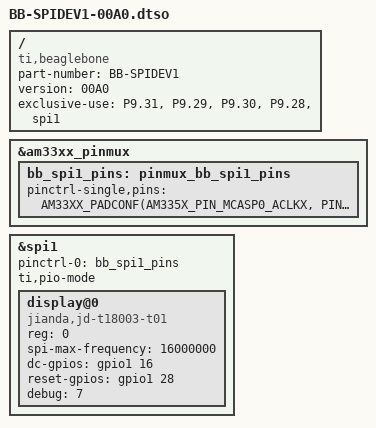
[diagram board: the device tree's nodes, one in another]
/*
 * Copyright (C) 2013 CircuitCo
 *
 * Virtual cape for SPI1 on connector pins P9.29 P9.31 P9.30 P9.28
 *
 * This program is free software; you can redistribute it and/or modify
 * it under the terms of the GNU General Public License version 2 as
 * published by the Free Software Foundation.
 */

#include <dt-bindings/gpio/gpio.h>
#include <dt-bindings/pinctrl/am33xx.h>

/dts-v1/;
/plugin/;

/ {
	compatible = "ti,beaglebone", "ti,beaglebone-black", "ti,beaglebone-green";

	/* identification */
	part-number = "BB-SPIDEV1";
	version = "00A0";

	/* state the resources this cape uses */
	exclusive-use =
		/* the pin header uses */
		"P9.31",	/* spi1_sclk */
		"P9.29",	/* spi1_d0 */
		"P9.30",	/* spi1_d1 */
		"P9.28",	/* spi1_cs0 */
		// "P9.42",	/* spi1_cs1 */
		/* the hardware ip uses */
		"spi1";

	fragment@0 {
                target = <&am33xx_pinmux>;
                __overlay__ {
                        bb_spi1_pins: pinmux_bb_spi1_pins {
                                pinctrl-single,pins = <
                                        AM33XX_PADCONF(AM335X_PIN_MCASP0_ACLKX, PIN_INPUT, MUX_MODE3)   /* SCLK */
                                        AM33XX_PADCONF(AM335X_PIN_MCASP0_FSX, PIN_INPUT, MUX_MODE3)     /* MOSI */
                                        AM33XX_PADCONF(AM335X_PIN_MCASP0_AXR0, PIN_INPUT, MUX_MODE3)    /* MISO */
                                        AM33XX_PADCONF(AM335X_PIN_MCASP0_AHCLKR, PIN_INPUT, MUX_MODE3)  /* CS0 */
                                >;
                        };
                };
        };
	
	fragment@1 {
		target = <&spi1>;
		__overlay__ {
			#address-cells = <1>;
			#size-cells = <0>;

			status = "okay";
			pinctrl-names = "default";
			pinctrl-0 = <&bb_spi1_pins>;
			ti,pio-mode; /* disable dma when used as an overlay, dma gets stuck at 160 bits... */

			/*channel@0 {
				#address-cells = <1>;
				#size-cells = <0>;

				compatible = "spidev";

				reg = <0>;
				spi-max-frequency = <16000000>;
				spi-cpha;
			};

			channel@1 {
				#address-cells = <1>;
				#size-cells = <0>;

				compatible = "spidev";

				reg = <1>;
				spi-max-frequency = <16000000>;
			};*/

                       display@0{
                               status = "okay";
			       /*mipi-dbi;*/ /* This is also experimental */
                               compatible = "jianda,jd-t18003-t01", "sitronix,st7735r"; /*"jianda,jd-t18003-t01", "sitronix,st7735r";*/
                               reg = <0>;
                               spi-max-frequency = <16000000>;
                               /* https://elinux.org/Beagleboard:Cape_Expansion_Headers */
                               dc-gpios = <&gpio1 16 0>;    /* dc:48    P9.15 GPIO1_16 */
                               reset-gpios = <&gpio1 28 0>; /* reset:60 P9.12 GPIO1_28 */
			       /*buswidth = <8>;*/ /*This is expiremental*/
			       debug = <7>;
                               /* rotation = <270>; */
			       /*bgr = <1>;*/           /* BGR color order instead of RGB */
				
                       };


		};
	};
};
